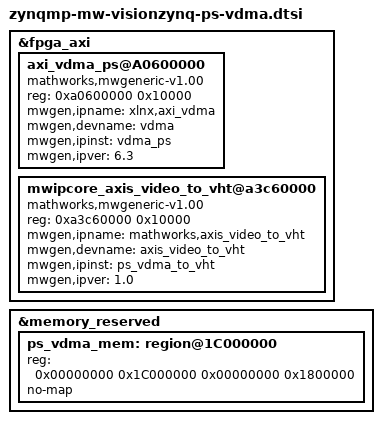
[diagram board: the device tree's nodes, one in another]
&fpga_axi {	
	axi_vdma_ps@A0600000 {
		compatible = "mathworks,mwgeneric-v1.00";
		reg = <0xa0600000 0x10000>;
		mwgen,ipname = "xlnx,axi_vdma";
		mwgen,devname = "vdma";
		mwgen,ipinst = "vdma_ps";
		mwgen,ipver = "6.3";
	};
	
	mwipcore_axis_video_to_vht@a3c60000 {
		compatible = "mathworks,mwgeneric-v1.00";
		reg = <0xa3c60000 0x10000>;
		mwgen,ipname = "mathworks,axis_video_to_vht";
		mwgen,devname = "axis_video_to_vht";
		mwgen,ipinst = "ps_vdma_to_vht";
		mwgen,ipver = "1.0";
	};
};

&memory_reserved {
	ps_vdma_mem: region@1C000000 {
		reg = <0x00000000 0x1C000000 0x00000000 0x1800000>;
		no-map;
	};
};


